# TLE984x register map
Vendor: Infineon Technologies AG; File version: 1.6
CPU: CM0 r0p0, little endian, no MPU, no FPU, 2 interrupt priority bits
Registers are 32-bit, read-write, no defined reset value unless marked. A register's access mark holds for its fields unless they carry their own. Offsets are from the block's base; [hi:lo] are bit positions; {n}, {i} and the like mark numbered series; 'fields as' and 'values as' point back to an identical list.

## ADC2
Base 0x4801C000
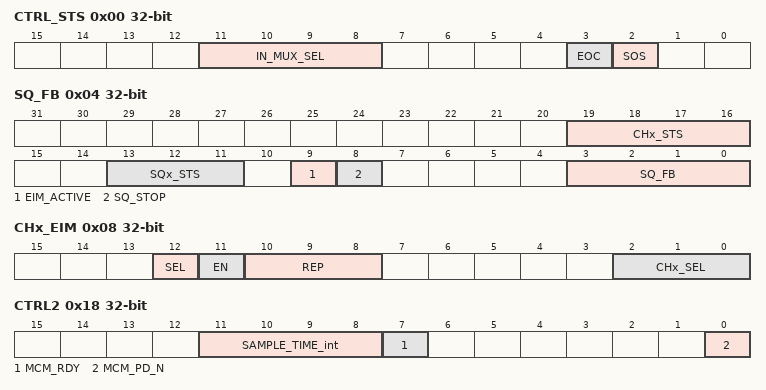
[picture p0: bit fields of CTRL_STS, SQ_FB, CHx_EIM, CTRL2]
0x00 CTRL_STS access per field — ADC2 Control and Status Register
  [11:8] IN_MUX_SEL rw — Channel for software mode
    {v}=CH{v}_EN (Channel {v} enable) (v=0..6)
  [3] EOC ro — ADC2 End of Conversion (software mode)
    0=Pending (conversion still running); 1=Finished (conversion has finished)
  [2] SOS rw — ADC2 Start of Sampling/Conversion (software mode)
    0=Disable (no conversion is started); 1=Enable (conversion is started)
0x04 SQ_FB ro — Sequencer Feedback Register
  [19:16] CHx_STS — Current ADC2 Channel
    {v}=CH{v} (Channel {v} enable) (v=0..6)
  [13:11] SQx_STS — Current Active ADC2 Sequence
    {v}=SQ{v+1} (Sequence {v+1} enable) (v=0..6)
  [9] EIM_ACTIVE — ADC2 EIM active
    0=not active (EIM not active); 1=active (EIM active)
  [8] SQ_STOP — ADC2 Sequencer Stop Signal for DPP
    0=DPP Running (Postprocessing Sequencer in running mode); 1=DPP Stopped (Postprocessing Sequencer stopped / Software Mode entered)
  [3:0] SQ_FB — Current Sequence that caused software mode
    {v}=SQ{v+1} (Sequence {v+1}) (v=0..6); 11=CH_MASK (Channel Mask = 0); 12=SUSPEND (Debug Suspend Mode)
0x08 CHx_EIM — Channel Settings Bits for Exceptional Interrupt Measurement
  [12] SEL — Exceptional interrupt measurement (EIM) Trigger select
    0=GPT12PISEL.T3_GPT12_SEL (GPT12_PISEL triggers EIM); 1=not supported
  [11] EN — Exceptional interrupt measurement (EIM) Trigger Event enable
    0=DISABLE (start of EIM disabled); 1=ENABLE (start of IEM enabled)
  [10:8] REP — Repeat count for exceptional interrupt measurement (EIM)
    {v}=Measurements (v=0..7)
  [2:0] CHx_SEL — Channel set for exceptional interrupt measurement (EIM)
    {v}=CH{v}_EN (Channel {v} enable) (v=0..6)
0x10 MAX_TIME — Maximum Time for Software Mode
  [7:0] MAX_TIME — Maximum Time in Software Mode
    0=min (Software mode is immediately left); 255=max (Software mode is active for 12.75 us)
0x14 CTRL1 ro — Measurement Unit Control Register 1
  [6:0] CALIB_EN_6_0 — Calibration Enable for Channels 6 to 0
    1=CH0_EN (Channel 0 calibration enable); 2=CH1_EN (Channel 1 calibration enable); 4=CH2_EN (Channel 2 calibration enable); 8=CH3_EN (Channel 3 calibration enable); 16=CH4_EN (Channel 4 calibration enable); 32=CH5_EN (Channel 5 calibration enable); 64=CH6_EN (Channel 6 calibration enable)
0x18 CTRL2 access per field — Measurement Unit Control Register 2
  [11:8] SAMPLE_TIME_int rw — Sample time of ADC2
    0=MICLK4 (4 MI_CLK clock periods); 1=MICLK6 (6 MI_CLK clock periods); 2=MICLK8 (8 MI_CLK clock periods); 3=MICLK10 (10 MI_CLK clock periods); 4=MICLK12 (12 MI_CLK clock periods (default)); 5=MICLK14 (14 MI_CLK clock periods); 6=MICLK16 (16 MI_CLK clock periods); 7=MICLK18 (18 MI_CLK clock periods); 8=MICLK20 (20 MI_CLK clock periods); 9=MICLK22 (22 MI_CLK clock periods)
  [7] MCM_RDY ro — Ready Signal for MCM after Power On or Reset
    0=MCM Not Ready (Measurement Core Module in startup phase); 1=MCM Ready (Measurement Core Module start-up phase finished)
  [0] MCM_PD_N ro — Power Down Signal for MCM
    0=MCM Disabled (Measurement Core Module disabled); 1=MCM Enabled (Measurement Core Module enabled)
0x1C CTRL4 — Measurement Unit Control Register 4
  [6:0] FILT_OUT_SEL_6_0 — Output Filter Selection for Channels 0 to 6
    0=ADC2 Unfiltered Data can be monitored in the corresponding ADC2_FILT_OUTx Registers; 1=Channel 0 IIR Data enabled for ADC2_FILT_OUT0 Register; 2=Channel 1 IIR Data enabled for ADC2_FILT_OUT1 Register; 4=Channel 2 IIR Data enabled for ADC2_FILT_OUT2 Register; 8=Channel 3 IIR Data enabled for ADC2_FILT_OUT3 Register; 16=Channel 4 IIR Data enabled for ADC2_FILT_OUT4 Register; 32=Channel 5 IIR Data enabled for ADC2_FILT_OUT5 Register; 64=Channel 6 IIR Data enabled for ADC2_FILT_OUT6 Register; 127=For Channels 6-0 IIR Data is enabled for ADC2_FILT_OUTx Registers
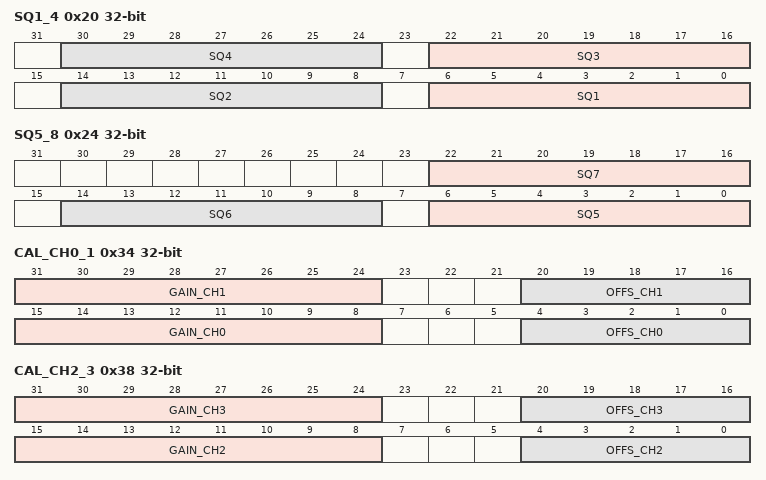
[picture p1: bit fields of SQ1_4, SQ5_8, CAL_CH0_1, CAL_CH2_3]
0x20 SQ1_4 ro — Measurement Channel Enable Bits for Cycle 1-4
  [all] fields
    1=CH0_EN (Channel 0 enable); 2=CH1_EN (Channel 1 enable); 4=CH2_EN (Channel 2 enable); 8=CH3_EN (Channel 3 enable); 16=CH4_EN (Channel 4 enable); 32=CH5_EN (Channel 5 enable); 64=CH6_EN (Channel 6 enable)
  [8n-2:8n-8] SQ{n} (n=1..4) — Sequence {n} channel enable
0x24 SQ5_8 ro — Measurement Channel Enable Bits for Cycle 5 - 8
  [all] fields
    values as the fields of SQ1_4
  [22:16] SQ7 — Sequence 7 channel enable
  [14:8] SQ6 — Sequence 6 channel enable
  [6:0] SQ5 — Sequence 5 channel enable
0x34 CAL_CH0_1 ro — Calibration for Channel 0 & 1
  [31:24] GAIN_CH1 — Gain Calibration for channel 1
  [20:16] OFFS_CH1 — Offset Calibration for channel 1
  [15:8] GAIN_CH0 — Gain Calibration for channel 0
  [4:0] OFFS_CH0 — Offset Calibration for channel 0
0x38 CAL_CH2_3 ro — Calibration for Channel 2 & 3
  [31:24] GAIN_CH3 — Gain Calibration for channel 3
  [20:16] OFFS_CH3 — Offset Calibration for channel 3
  [15:8] GAIN_CH2 — Gain Calibration for channel 2
  [4:0] OFFS_CH2 — Offset Calibration for channel 2
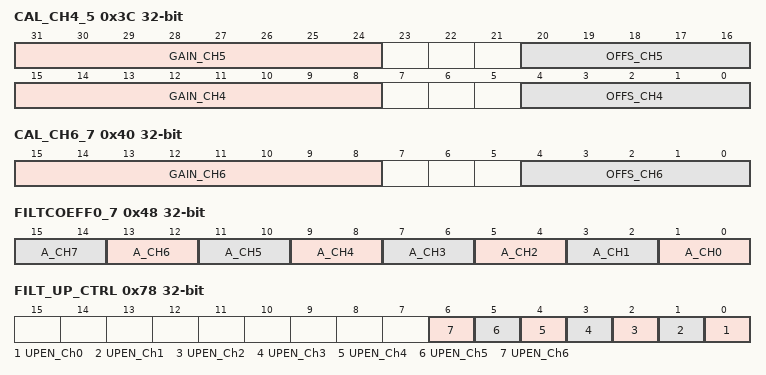
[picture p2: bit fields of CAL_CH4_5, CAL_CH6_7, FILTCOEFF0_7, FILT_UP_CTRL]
0x3C CAL_CH4_5 ro — Calibration for Channel 4 & 5
  [31:24] GAIN_CH5 — Gain Calibration for channel 5
  [20:16] OFFS_CH5 — Offset Calibration for channel 5
  [15:8] GAIN_CH4 — Gain Calibration for channel 4
  [4:0] OFFS_CH4 — Offset Calibration for channel 4
0x40 CAL_CH6_7 ro — Calibration for Channel 6 & 7
  [15:8] GAIN_CH6 — Gain Calibration for channel 6
  [4:0] OFFS_CH6 — Offset Calibration for channel 6
0x48 FILTCOEFF0_7 ro — Filter Coefficients ADC Channel 0-7
  [all] fields
    0=1/2 (weight of current sample); 1=1/4 (weight of current sample); 2=1/8 (weight of current sample); 3=1/16 (weight of current sample)
  [2n+1:2n] A_CH{n} (n=0..7) — Filter Coefficient A for ADC channel {n}
{0x50+4i} FILT_OUT{i} ro (i=0..6) — ADC or Filter Output Channel {i}
  [9:0] OUT_CH{i} — ADC or filter output value channel {i}
0x78 FILT_UP_CTRL — Upper Threshold Filter Enable
  [all] fields
    0=disable; 1=enable
  [n] UPEN_Ch{n} (n=0..6) — Upper threshold IIR filter enable ch {n}
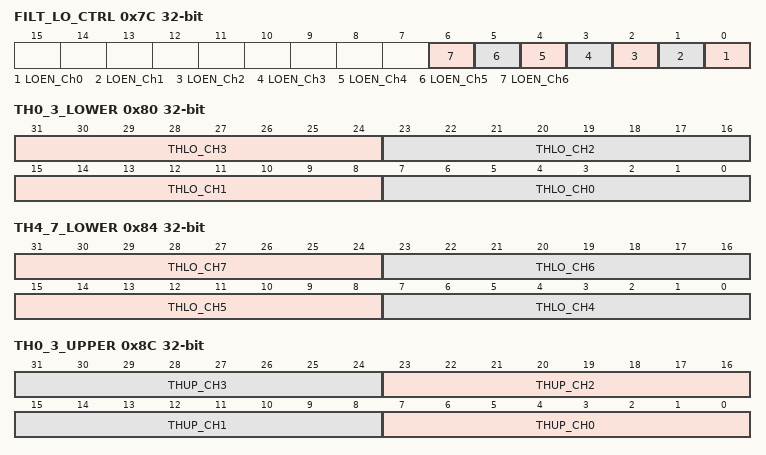
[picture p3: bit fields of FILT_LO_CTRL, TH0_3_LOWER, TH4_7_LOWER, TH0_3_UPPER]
0x7C FILT_LO_CTRL — Lower Threshold Filter Enable
  [all] fields
    0=disable; 1=enable
  [n] LOEN_Ch{n} (n=0..6) — Lower threshold IIR filter enable ch {n}
0x80 TH0_3_LOWER access per field — Lower Comparator Trigger Level Channel 0 -3
  [all] fields
    0=Min. threshold value; 255=Max. threshold value
  [31:24] THLO_CH3 ro — Channel 3 lower trigger level
  [23:16] THLO_CH2 ro — Channel 2 lower trigger level
  [15:8] THLO_CH1 rw — Channel 1 lower trigger level
  [7:0] THLO_CH0 ro — Channel 0 lower trigger level
0x84 TH4_7_LOWER access per field — Lower Comparator Trigger Level Channel 4 to 7
  [all] fields
    0=Min. threshold value; 255=Max. threshold value
  [31:24] THLO_CH7 rw — Channel 7 lower trigger level
  [23:16] THLO_CH6 rw — Channel 6 lower trigger level
  [15:8] THLO_CH5 rw — Channel 5 lower trigger level
  [7:0] THLO_CH4 ro — Channel 4 lower trigger level
0x8C TH0_3_UPPER — Upper Comparator Trigger Level Channel 0-3
  [all] fields
    0=min. threshold value = 0; 255=max. threshold value = 255
  [8n+7:8n] THUP_CH{n} (n=0..3) — Channel {n} upper trigger level
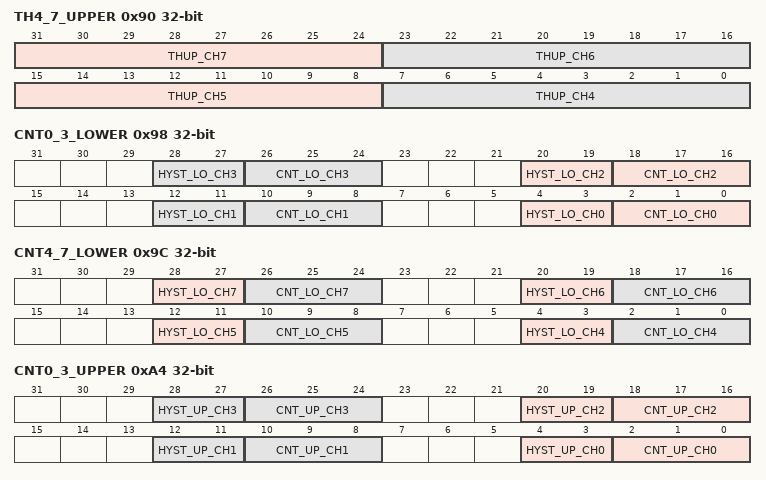
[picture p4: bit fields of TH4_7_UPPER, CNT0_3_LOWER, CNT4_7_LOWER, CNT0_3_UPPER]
0x90 TH4_7_UPPER ro — Upper Comparator Trigger Level Channel 4 -7
  [31:24] THUP_CH7 — Channel 7 upper trigger level
    0=min. threshold value = 0; 255=max. threshold value = 255
  [23:16] THUP_CH6 — Channel 6 upper trigger level
    0=min threshold value = 0; 255=max. threshold value = 255
  [15:8] THUP_CH5 — Channel 5 upper trigger level
    0=min. threshold value = 0; 255=max. threshold value = 255
  [7:0] THUP_CH4 — Channel 4 upper trigger level
    0=min. threshold value = 0; 255=max. threshold value = 255
0x98 CNT0_3_LOWER — Lower Counter Trigger Level Channel 0 - 3
  [8n+4:8n+3] HYST_LO_CH{n} (n=0..3) — Channel {n} lower hysteresis
    0=HYSTOFF (hysteresis switched off); 1=HYST4 (hysteresis = 4); 2=HYST8 (hysteresis = 8); 3=HYST16 (hysteresis = 16)
  [8n+2:8n] CNT_LO_CH{n} (n=0..3) — Lower timer trigger threshold channel {n}
    0=1 measurement; 1=2 measurements; 2=4 measurements; 3=8 measurements; 4=16 measurements; 5=32 measurements; 6=63 measurements; 7=63 measurements
0x9C CNT4_7_LOWER — Lower Counter Trigger Level Channel 4 to 7
  [28:27] HYST_LO_CH7 — Channel 6 lower hysteresis
    values as CNT0_3_LOWER.HYST_LO_CH0
  [26:24] CNT_LO_CH7 — Lower timer trigger threshold channel 6
    values as CNT0_3_LOWER.CNT_LO_CH0
  [20:19] HYST_LO_CH6 — Channel 6 lower hysteresis
    values as CNT0_3_LOWER.HYST_LO_CH0
  [18:16] CNT_LO_CH6 — Lower timer trigger threshold channel 6
    values as CNT0_3_LOWER.CNT_LO_CH0
  [12:11] HYST_LO_CH5 — Channel 5 lower hysteresis
    values as CNT0_3_LOWER.HYST_LO_CH0
  [10:8] CNT_LO_CH5 — Lower timer trigger threshold channel 5
    values as CNT0_3_LOWER.CNT_LO_CH0
  [4:3] HYST_LO_CH4 — Channel 4 lower hysteresis
    values as CNT0_3_LOWER.HYST_LO_CH0
  [2:0] CNT_LO_CH4 — Lower timer trigger threshold channel 4
    values as CNT0_3_LOWER.CNT_LO_CH0
0xA4 CNT0_3_UPPER — Upper Counter Trigger Level Channel 0 - 3
  [8n+4:8n+3] HYST_UP_CH{n} (n=0..3) — Channel {n} upper hysteresis
    values as CNT0_3_LOWER.HYST_LO_CH0
  [8n+2:8n] CNT_UP_CH{n} (n=0..3) — Upper timer trigger threshold channel {n}
    values as CNT0_3_LOWER.CNT_LO_CH0
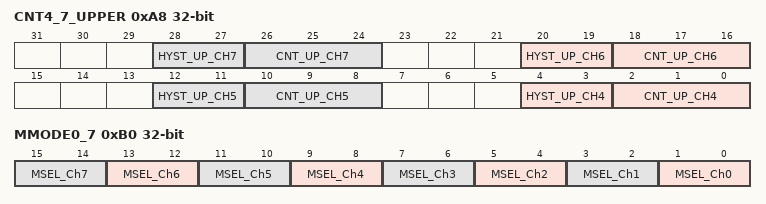
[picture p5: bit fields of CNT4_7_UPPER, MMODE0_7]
0xA8 CNT4_7_UPPER — Upper Counter Trigger Level Channel 4 to 7
  [8n-28:8n-29] HYST_UP_CH{n} (n=4..7) — Channel {n} upper hysteresis
    values as CNT0_3_LOWER.HYST_LO_CH0
  [8n-30:8n-32] CNT_UP_CH{n} (n=4..7) — Upper timer trigger threshold channel {n}
    values as CNT0_3_LOWER.CNT_LO_CH0
0xB0 MMODE0_7 ro — Measurement Mode of Ch 0-7
  [all] fields
    0=MMODE0 (upper & lower voltage/limit measurement); 1=MMODEUV (undervoltage/-limit measurement); 2=MMODEOV (overvoltage/-limit measurement)
  [2n+1:2n] MSEL_Ch{n} (n=0..7) — Measurement mode ch {n}
0xBC STATUS ro — ADC2 HV Status Register
  [1] READY — HVADC Ready bit
    0=Not ready (Module in power down or in init phase); 1=Ready (set automatically 5 ADC clock cycles after module is enabled)
